# CC23x0 register map
File version: 1.1
CPU: CM0+ r0p4, little endian, no MPU, no FPU, VTOR, 3 interrupt priority bits
Registers are 32-bit, read-write, reset 0x0 unless marked. A register's access mark holds for its fields unless they carry their own. Offsets are from the block's base; [hi:lo] are bit positions; lines under a group give offsets from that group; 'fields as' and 'values as' point back to an identical list.

## LRFDTXF
Base 0x40081800
0x00 TXD — TX FIFO data. When written the register data is pushed to the TX FIFO. When read, data is popped from the TX FIFO
  [31:0] DATA — TX FIFO data. When written the register data is pushed to the TX FIFO. When read, data is popped from the TX FIFO. When writing or reading this register the access size will determine how many bytes are pushed to or popped from the FIFO. It is possible to push or pop 1,2 or 4 bytes depending on the access being done.

## EVTULL — This is top module of ULL Event Fabric
Base 0x40005000
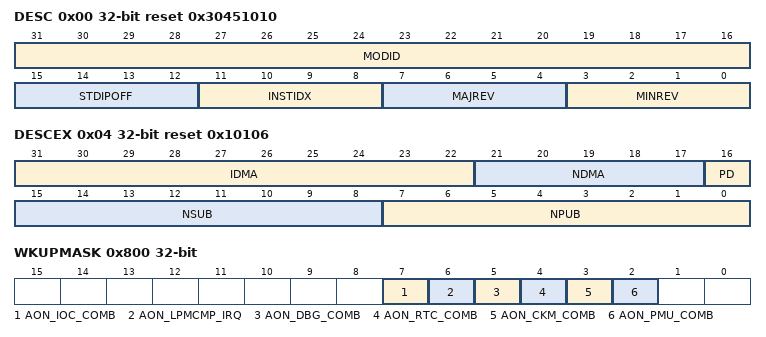
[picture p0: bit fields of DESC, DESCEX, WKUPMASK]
0x00 DESC ro reset 0x30451010 — Description This register provides IP module ID, revision information, instance index and standard MMR registers offset.
  [31:16] MODID — Module identifier used to uniquely identify this IP.
  [15:12] STDIPOFF — Standard IP MMR block offset. Standard IP MMRs are the set of from aggregated IRQ registers till DTB. 0: Standard IP MMRs do not exist 0x1-0xF: Standard IP MMRs begin at offset of (64*STDIPOFF from the base IP address)
  [11:8] INSTIDX — IP Instance ID number. If multiple instances of IP exist in the device, this field can identify the instance number (0-15).
  [7:4] MAJREV — Major revision of IP (0-15).
  [3:0] MINREV — Minor revision of IP (0-15).
0x04 DESCEX ro reset 0x10106 — Extended Description This register provides configuration details of the IP to software drivers and end users.
  [31:22] IDMA — Number of DMA input channels
  [21:17] NDMA — Number of DMA output channels
  [16] PD — Power Domain. 0 : SVT 1 : ULL
  [15:8] NSUB — Number of Subscribers
  [7:0] NPUB — Number of Publishers
0x64 DTB — Digital test bus control register This register can be used to bring out IP internal signals to the pads for observation. 16 signals can be observed per select value.
  [0] SEL — Digital test bus selection mux control Non-zero select values output a 16 bit selected group of signals per value.
    0=DIS (All 16 observation signals are set to zero.)
0x400 NMISEL — Output Selection for CPU NMI Exception
  [5:0] PUBID — Read/write selection value. Writing any other value than values defined by a ENUM may result in undefined behavior.
    7=AON_IOC_COMB (IOC synchronous combined event, controlled by IOC:EVTCFG); 6=AON_LPMCMP_IRQ (AON LPCMP interrupt, controlled by SYS0:LPCMPCFG); 5=AON_DBG_COMB (DebugSS combined interrupt, interrupt flags can be found here DBGSS:MIS); 4=AON_RTC_COMB (AON_RTC event, controlled by the RTC:IMASK setting); 3=AON_CKM_COMB (CKMD combined interrupt request, interrupt flags can be found here CKMD:MIS); 2=AON_PMU_COMB (PMU combined interrupt request for BATMON, interrupt flags can be found here PMUD:EVENT); 0=NONE (Always inactive)
0x404 RTCCPTSEL — Output Selection for RTCCPT
  fields as NMISEL
0x800 WKUPMASK — WAKEUP Mask
  [7] AON_IOC_COMB — Wake-up mask for AON_IOC_COMB. 0 - Wakeup Disabled 1 - Wakeup Enabled
  [6] AON_LPMCMP_IRQ — Wake-up mask for AON_LPMCMP_IRQ. 0 - Wakeup Disabled 1 - Wakeup Enabled
  [5] AON_DBG_COMB — Wake-up mask for AON_DBG_COMB. 0 - Wakeup Disabled 1 - Wakeup Enabled
  [4] AON_RTC_COMB — Wake-up mask for AON_RTC_COMB. 0 - Wakeup Disabled 1 - Wakeup Enabled
  [3] AON_CKM_COMB — Wake-up mask for AON_CKM_COMB. 0 - Wakeup Disabled 1 - Wakeup Enabled
  [2] AON_PMU_COMB — Wake-up mask for AON_PMU_COMB. 0 - Wakeup Disabled 1 - Wakeup Enabled

## SYSTICK
Base 0xE000E010
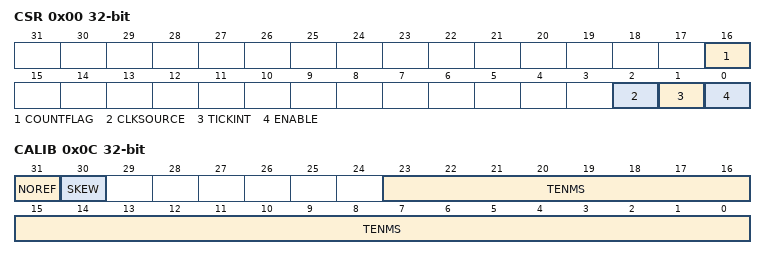
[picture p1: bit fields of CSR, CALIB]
0x00 CSR — SysTick Control and Status Register Use the SysTick Control and Status Register to enable the SysTick features.
  [16] COUNTFLAG ro — Returns 1 if timer counted to 0 since last time this was read. Clears on read by application or debugger.
  [2] CLKSOURCE ro — SysTick clock source. Always reads as one if STCALIB reports NOREF. 0x0:Systick driven by external reference clock. 0x1:Systick driven by processor clock
  [1] TICKINT — 0x0:Counting down to zero does not pend the systick handler. software can use countflag to determine if the systick handler has ever counted to zero. 0x1:Counting down to zero pends the systick handler.
  [0] ENABLE — Enable SysTick counter 0x0:Counter disabled 0x1:Counter operates in a multi-shot way. that is, counter loads with the reload value and then begins counting down. on reaching 0, it sets the countflag to 1 and optionally pends the systick handler, based on tickint. it then loads the reload value again, and begins counting.
0x04 RVR — SysTick Reload Value Register Use the SysTick Reload Value Register to specify the start value to load into the current value register when the counter reaches 0. It can be any value between 0 and 0x00FFFFFF. A start value of 0 is possible, but has no effect because the SysTick interrupt and COUNTFLAG are activated when counting from 1 to 0. The reset value of this register is UNKNOWN.
  [23:0] RELOAD — Value to load into the SysTick Current Value Register when the counter reaches 0.
0x08 CVR — SysTick Current Value Register Use the SysTick Current Value Register to find the current value in the register. The reset value of this register is UNKNOWN.
  [23:0] CURRENT — Reads return the current value of the SysTick counter. This register is write-clear. Writing to it with any value clears the register to 0. Clearing this register also clears the COUNTFLAG bit of the SysTick Control and Status Register.
0x0C CALIB — SysTick Calibration Value Register Use the SysTick Calibration Value Register to enable software to scale to any required speed using divide and multiply.
  [31] NOREF ro — If reads as 1, the Reference clock is not provided - the CLKSOURCE bit of the SysTick Control and Status register will be forced to 1 and cannot be cleared to 0.
  [30] SKEW ro — If reads as 1, the calibration value for 10ms is inexact (due to clock frequency).
  [23:0] TENMS ro — An optional Reload value to be used for 10ms (100Hz) timing, subject to system clock skew errors. If the value reads as 0, the calibration value is not known.
